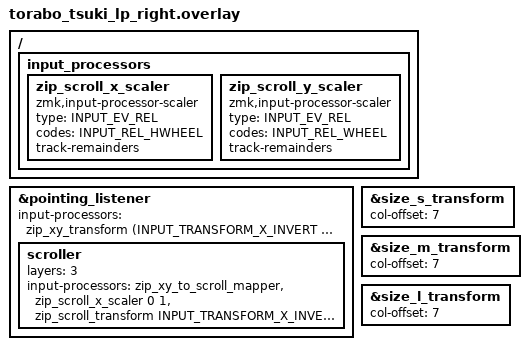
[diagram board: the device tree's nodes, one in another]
#include "torabo_tsuki_lp.dtsi"
#include <input/processors.dtsi>
#include <dt-bindings/zmk/input_transform.h>

&pointing_listener {
    input-processors = <&zip_xy_transform (INPUT_TRANSFORM_X_INVERT | INPUT_TRANSFORM_Y_INVERT)>;
};

&size_s_transform {
    col-offset = <7>;
};

&size_m_transform {
    col-offset = <7>;
};

&size_l_transform {
    col-offset = <7>;
};
/ {
    input_processors {
        zip_scroll_x_scaler: zip_scroll_x_scaler {
            compatible = "zmk,input-processor-scaler";
            #input-processor-cells = <2>;
            type = <INPUT_EV_REL>;
            codes = <INPUT_REL_HWHEEL>;
            track-remainders;
        };

        zip_scroll_y_scaler: zip_scroll_y_scaler {
            compatible = "zmk,input-processor-scaler";
            #input-processor-cells = <2>;
            type = <INPUT_EV_REL>;
            codes = <INPUT_REL_WHEEL>;
            track-remainders;
        };
    };
};

&pointing_listener {
    scroller {
        layers = <3>;
        input-processors = <
            &zip_xy_to_scroll_mapper
            &zip_scroll_x_scaler 0 1
            &zip_scroll_transform INPUT_TRANSFORM_X_INVERT
        >;
    };
};
